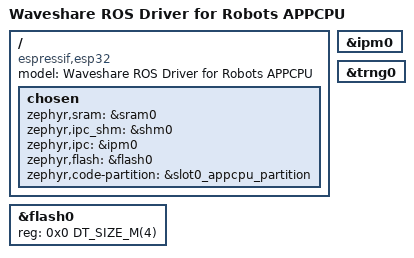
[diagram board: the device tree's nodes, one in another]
/dts-v1/;

#include <espressif/esp32/esp32_appcpu.dtsi>
#include <espressif/partitions_0x1000_amp_4M.dtsi>

/ {
	model = "Waveshare ROS Driver for Robots APPCPU";
	compatible = "espressif,esp32";

	chosen {
		zephyr,sram = &sram0;
		zephyr,ipc_shm = &shm0;
		zephyr,ipc = &ipm0;
		zephyr,flash = &flash0;
		zephyr,code-partition = &slot0_appcpu_partition;
	};
};

&ipm0 {
	status = "okay";
};

&trng0 {
	status = "okay";
};

/* Must match the PROCPU flash: esp32_appcpu.dtsi no longer sets reg or ranges,
 * and the partition table above describes the same physical flash.
 */
&flash0 {
	reg = <0x0 DT_SIZE_M(4)>;
	ranges = <0x0 0x0 DT_SIZE_M(4)>;
	status = "okay";
};
